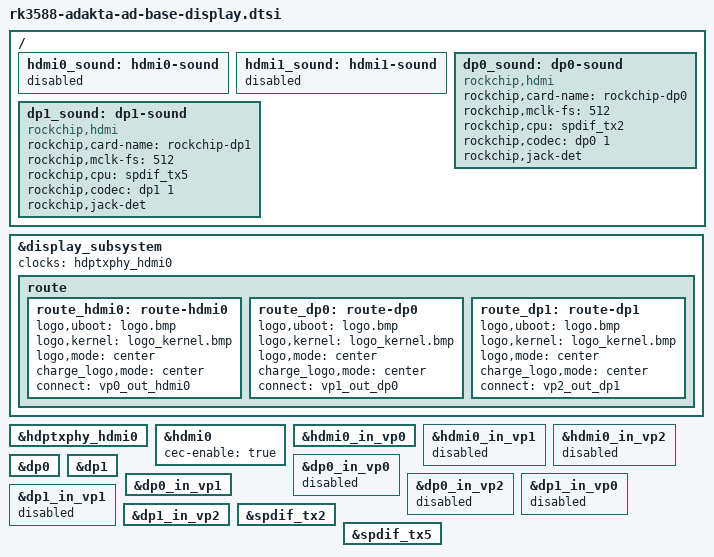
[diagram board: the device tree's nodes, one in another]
// SPDX-License-Identifier: (GPL-2.0+ OR MIT)
/*
 * Copyright (c) 2024 Adakta, Ltd.
 *
 */

/ {
	hdmi0_sound: hdmi0-sound {
		status = "disable";
	};

	hdmi1_sound: hdmi1-sound {
		status = "disable";
	};

	dp0_sound: dp0-sound {
		status = "okay";
		compatible = "rockchip,hdmi";
		rockchip,card-name = "rockchip-dp0";
		rockchip,mclk-fs = <512>;
		rockchip,cpu = <&spdif_tx2>;
		rockchip,codec = <&dp0 1>;
		rockchip,jack-det;
	};

	dp1_sound: dp1-sound {
		status = "okay";
		compatible = "rockchip,hdmi";
		rockchip,card-name = "rockchip-dp1";
		rockchip,mclk-fs = <512>;
		rockchip,cpu = <&spdif_tx5>;
		rockchip,codec = <&dp1 1>;
		rockchip,jack-det;
	};
};

&display_subsystem {
	clocks = <&hdptxphy_hdmi0>;
	clock-names = "hdmi0_phy_pll";

	route {
		route_hdmi0: route-hdmi0 {
			status = "okay";
			logo,uboot = "logo.bmp";
			logo,kernel = "logo_kernel.bmp";
			logo,mode = "center";
			charge_logo,mode = "center";
			connect = <&vp0_out_hdmi0>;
		};

		route_dp0: route-dp0 {
			status = "ok";
			logo,uboot = "logo.bmp";
			logo,kernel = "logo_kernel.bmp";
			logo,mode = "center";
			charge_logo,mode = "center";
			connect = <&vp1_out_dp0>;
		};

		route_dp1: route-dp1 {
			status = "ok";
			logo,uboot = "logo.bmp";
			logo,kernel = "logo_kernel.bmp";
			logo,mode = "center";
			charge_logo,mode = "center";
			connect = <&vp2_out_dp1>;
		};
	};
};

&hdptxphy_hdmi0 {
	status = "okay";
};

&hdmi0 {
	status = "okay";
        cec-enable = "true";
};

&hdmi0_in_vp0 {
	status = "okay";
};

&hdmi0_in_vp1 {
	status = "disabled";
};

&hdmi0_in_vp2 {
	status = "disabled";
};

&hdptxphy_hdmi0 {
	status = "okay";
};

&dp0 {
	status = "okay";
};

&dp1 {
	status = "okay";
};

&dp0_in_vp0 {
	status = "disabled";
};

&dp0_in_vp1 {
	status = "okay";
};

&dp0_in_vp2 {
	status = "disabled";
};

&dp1_in_vp0 {
	status = "disabled";
};

&dp1_in_vp1 {
	status = "disabled";
};

&dp1_in_vp2 {
	status = "okay";
};

&spdif_tx2 {
	status = "okay";
};

&spdif_tx5 {
	status = "okay";
};
